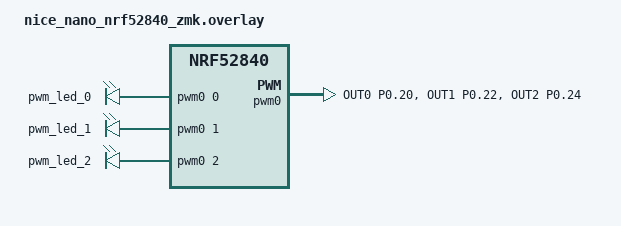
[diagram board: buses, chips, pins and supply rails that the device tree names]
#include <dt-bindings/led/led.h>
#include <dt-bindings/pwm/pwm.h>

// &pwm0 {
//   status = "okay";
//   pinctrl-0 = <&pwm0_default>;
//   pinctrl-1 = <&pwm0_sleep>;
//   pinctrl-names = "default", "sleep";
// };

// &pinctrl {
//     pwm0_default: pwm0_default {
//         group1 {
//             // Use P1.04 for LED backlight
//             psels = <NRF_PSEL(PWM_OUT0, 0, 20)>;
// 	      };
//         group2 {
//             // Use P1.04 for LED backlight
//             psels = <NRF_PSEL(PWM_OUT0, 0, 22)>;
// 	      };
//         group3 {
//             // Use P1.04 for LED backlight
//             psels = <NRF_PSEL(PWM_OUT0, 0, 24)>;
// 	      };
//     };

//     pwm0_sleep: pwm0_sleep {
//         group1 {
//             // Use P1.04 for LED backlight
//             psels = <NRF_PSEL(PWM_OUT0, 0, 20)>;
//             low-power-enable;
// 	      };
//         group2 {
//             // Use P1.04 for LED backlight
//             psels = <NRF_PSEL(PWM_OUT0, 0, 22)>;
//             low-power-enable;
// 	      };
//         group3 {
//             // Use P1.04 for LED backlight
//             psels = <NRF_PSEL(PWM_OUT0, 0, 24)>;
//             low-power-enable;
// 	      };
//     };
// };

&pinctrl {
    pwm0_default: pwm0_default {
        group1 {
            psels = <NRF_PSEL(PWM_OUT0, 0, 20)>,
                    <NRF_PSEL(PWM_OUT1, 0, 22)>,
                    <NRF_PSEL(PWM_OUT2, 0, 24)>;
        };
    };

    pwm0_sleep: pwm0_sleep {
        group1 {
            psels = <NRF_PSEL(PWM_OUT0, 0, 20)>,
                    <NRF_PSEL(PWM_OUT1, 0, 22)>,
                    <NRF_PSEL(PWM_OUT2, 0, 24)>;
            low-power-enable;
        };
    };
};

&pwm0 {
    status = "okay";
    pinctrl-0 = <&pwm0_default>;
    pinctrl-1 = <&pwm0_sleep>;
    pinctrl-names = "default", "sleep";
};

/ {
    backlight: pwmleds {
        compatible = "pwm-leds";
        label = "Backlight LEDs";
        pwm_led_0 {
            pwms = <&pwm0 0 PWM_MSEC(10) PWM_POLARITY_NORMAL>;
        };
        pwm_led_1 {
            pwms = <&pwm0 1 PWM_MSEC(10) PWM_POLARITY_NORMAL>;
        };
        pwm_led_2 {
            pwms = <&pwm0 2 PWM_MSEC(10) PWM_POLARITY_NORMAL>;
        };
    };
};


/ {
    chosen {
        zmk,backlight = &backlight;
    };
};
